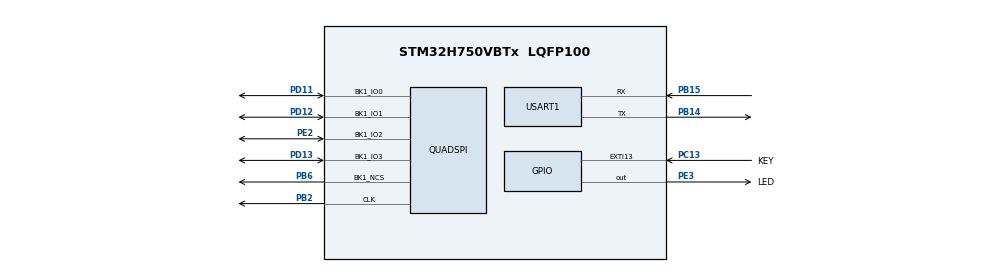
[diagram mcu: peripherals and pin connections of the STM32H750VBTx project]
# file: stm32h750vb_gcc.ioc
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CORTEX_M7.AccessPermission_S-Cortex_Memory_Protection_Unit_Region1_Settings_S=MPU_REGION_PRIV_RO
CORTEX_M7.BaseAddress_S-Cortex_Memory_Protection_Unit_Region1_Settings_S=0x08000000
CORTEX_M7.BaseAddress_Spec=QSPI_BASE
CORTEX_M7.CPU_DCache=Disabled
CORTEX_M7.CPU_ICache=Disabled
CORTEX_M7.DisableExec_Spec=MPU_INSTRUCTION_ACCESS_DISABLE
CORTEX_M7.Enable_S-Cortex_Memory_Protection_Unit_Region1_Settings_S=MPU_REGION_ENABLE
CORTEX_M7.IsCacheable_S-Cortex_Memory_Protection_Unit_Region1_Settings_S=MPU_ACCESS_CACHEABLE
CORTEX_M7.IsShareable_Spec=MPU_ACCESS_NOT_SHAREABLE
CORTEX_M7.Size_S-Cortex_Memory_Protection_Unit_Region1_Settings_S=MPU_REGION_SIZE_128KB
CORTEX_M7.Size_Spec=MPU_REGION_SIZE_256MB
CORTEX_M7.SubRegionDisable_Spec=0x00
CORTEX_M7.TypeExtField_Spec=MPU_TEX_LEVEL1
CORTEX_M7.default_mode_Activation=1
Dma.Request0=USART1_RX
Dma.USART1_RX.0.Direction=DMA_PERIPH_TO_MEMORY
Dma.USART1_RX.0.EventEnable=DISABLE
Dma.USART1_RX.0.FIFOMode=DMA_FIFOMODE_DISABLE
Dma.USART1_RX.0.Instance=DMA1_Stream0
Dma.USART1_RX.0.MemDataAlignment=DMA_MDATAALIGN_BYTE
Dma.USART1_RX.0.MemInc=DMA_MINC_ENABLE
Dma.USART1_RX.0.Mode=DMA_CIRCULAR
Dma.USART1_RX.0.PeriphDataAlignment=DMA_PDATAALIGN_BYTE
Dma.USART1_RX.0.PeriphInc=DMA_PINC_DISABLE
Dma.USART1_RX.0.Polarity=HAL_DMAMUX_REQ_GEN_RISING
Dma.USART1_RX.0.Priority=DMA_PRIORITY_LOW
Dma.USART1_RX.0.RequestNumber=1
Dma.USART1_RX.0.SignalID=NONE
Dma.USART1_RX.0.SyncEnable=DISABLE
Dma.USART1_RX.0.SyncPolarity=HAL_DMAMUX_SYNC_NO_EVENT
Dma.USART1_RX.0.SyncRequestNumber=1
Dma.USART1_RX.0.SyncSignalID=NONE
Mcu.Family=STM32H7
Mcu.Name=STM32H750VBTx
Mcu.Package=LQFP100
NVIC.DMA1_Stream0_IRQn=true\:0\:0\:false\:false\:true\:false\:true\:true
NVIC.EXTI15_10_IRQn=true\:0\:0\:true\:false\:true\:true\:true\:true
NVIC.PriorityGroup=NVIC_PRIORITYGROUP_4
NVIC.USART1_IRQn=true\:1\:0\:true\:false\:true\:false\:true\:true
PB14.GPIO_Speed=GPIO_SPEED_FREQ_MEDIUM
PB14.Mode=Asynchronous
PB14.Signal=USART1_TX
PB15.GPIO_Speed=GPIO_SPEED_FREQ_MEDIUM
PB15.Mode=Asynchronous
PB15.Signal=USART1_RX
PB2.GPIO_Speed=GPIO_SPEED_FREQ_VERY_HIGH
PB2.Mode=Single Bank 1
PB2.Signal=QUADSPI_CLK
PB6.GPIO_Speed=GPIO_SPEED_FREQ_VERY_HIGH
PB6.Mode=Single Bank 1
PB6.Signal=QUADSPI_BK1_NCS
PC13.GPIO_Label=KEY
PC13.Signal=GPXTI13
PC14-OSC32_IN\ (OSC32_IN).Mode=LSE-External-Oscillator
PC14-OSC32_IN\ (OSC32_IN).Signal=RCC_OSC32_IN
PC15-OSC32_OUT\ (OSC32_OUT).Mode=LSE-External-Oscillator
PC15-OSC32_OUT\ (OSC32_OUT).Signal=RCC_OSC32_OUT
PD11.GPIO_Speed=GPIO_SPEED_FREQ_VERY_HIGH
PD11.Mode=Single Bank 1
PD11.Signal=QUADSPI_BK1_IO0
PD12.GPIO_Speed=GPIO_SPEED_FREQ_VERY_HIGH
PD12.Mode=Single Bank 1
PD12.Signal=QUADSPI_BK1_IO1
PD13.GPIO_Speed=GPIO_SPEED_FREQ_VERY_HIGH
PD13.Mode=Single Bank 1
PD13.Signal=QUADSPI_BK1_IO3
PE2.GPIO_Speed=GPIO_SPEED_FREQ_VERY_HIGH
PE2.Mode=Single Bank 1
PE2.Signal=QUADSPI_BK1_IO2
PE3.GPIO_Label=LED
PE3.Signal=GPIO_Output
PH0-OSC_IN\ (PH0).Mode=HSE-External-Oscillator
PH0-OSC_IN\ (PH0).Signal=RCC_OSC_IN
PH1-OSC_OUT\ (PH1).Mode=HSE-External-Oscillator
PH1-OSC_OUT\ (PH1).Signal=RCC_OSC_OUT
ProjectManager.HeapSize=0x200
ProjectManager.StackSize=0x400
ProjectManager.TargetToolchain=Makefile
QUADSPI.ChipSelectHighTime=QSPI_CS_HIGH_TIME_6_CYCLE
QUADSPI.ClockMode=QSPI_CLOCK_MODE_3
QUADSPI.ClockPrescaler=1-1
QUADSPI.FifoThreshold=4
QUADSPI.FlashSize=23-1
QUADSPI.SampleShifting=QSPI_SAMPLE_SHIFTING_HALFCYCLE
RCC.ADCFreq_Value=100000000
RCC.APB1Freq_Value=120000000
RCC.APB2Freq_Value=120000000
RCC.APB3Freq_Value=120000000
RCC.APB4Freq_Value=120000000
RCC.CortexFreq_Value=480000000
RCC.D1PPRE=RCC_APB3_DIV2
RCC.D2PPRE1=RCC_APB1_DIV2
RCC.D2PPRE2=RCC_APB2_DIV2
RCC.D3PPRE=RCC_APB4_DIV2
RCC.DIVM1=5
RCC.DIVM2=25
RCC.DIVN1=192
RCC.DIVN2=200
RCC.DIVN3=128
RCC.DIVQ2=20
RCC.HCLKFreq_Value=240000000
RCC.HPRE=RCC_HCLK_DIV2
RCC.PLLSourceVirtual=RCC_PLLSOURCE_HSE
RCC.QSPICLockSelection=RCC_QSPICLKSOURCE_PLL2
RCC.SYSCLKFreq_VALUE=480000000
RCC.SYSCLKSource=RCC_SYSCLKSOURCE_PLLCLK
RCC.USART16CLockSelection=RCC_USART16CLKSOURCE_PLL2
RCC.USBFreq_Value=480000000
USART1.VirtualMode-Asynchronous=VM_ASYNC
VP_MEMORYMAP_VS_MEMORYMAP.Mode=CurAppReg
board=custom

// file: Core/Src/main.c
/* USER CODE BEGIN Header */
/**
 ******************************************************************************
 * @file           : main.c
 * @brief          : Main program body
 ******************************************************************************
 * @attention
 *
 * Copyright (c) 2024 STMicroelectronics.
 * All rights reserved.
 *
 * This software is licensed under terms that can be found in the LICENSE file
 * in the root directory of this software component.
 * If no LICENSE file comes with this software, it is provided AS-IS.
 *
 ******************************************************************************
 */
/* USER CODE END Header */
#include "main.h"
#include "dma.h"
#include "memorymap.h"
#include "quadspi.h"
#include "usart.h"
#include "gpio.h"

/* USER CODE BEGIN Includes */
#include "RingBuffer.h"
#include "w25qxx_qspi.h"
/* USER CODE END Includes */

/* USER CODE BEGIN PV */
uint8_t USART1_Rx_buf[1024] = {0};
uint8_t USART1_Tx_buf[1024] = {0};
RingBuffer usart1_fifo		= {0};
extern uint16_t w25qxx_ID;
/* USER CODE END PV */

void SystemClock_Config(void);
void PeriphCommonClock_Config(void);
static void MPU_Config(void);

int main(void)
{

	/* MPU Configuration--------------------------------------------------------*/
	MPU_Config();

	/* MCU Configuration--------------------------------------------------------*/

	/* Reset of all peripherals, Initializes the Flash interface and the Systick. */
	HAL_Init();

	/* USER CODE BEGIN Init */
	// SCB->CACR |= 1 << 2;
	/* USER CODE END Init */

	/* Configure the system clock */
	SystemClock_Config();

	/* Configure the peripherals common clocks */
	PeriphCommonClock_Config();

	/* Initialize all configured peripherals */
	MX_GPIO_Init();
	MX_DMA_Init();
	MX_USART1_UART_Init();
	MX_QUADSPI_Init();
	/* USER CODE BEGIN 2 */
	w25qxx_Init();
	printf("deviceID: 0x%x\n", w25qxx_ID);
	HAL_UARTEx_ReceiveToIdle_DMA(&huart1, USART1_Rx_buf, sizeof(USART1_Rx_buf));
	/* USER CODE END 2 */

	/* Infinite loop */
	/* USER CODE BEGIN WHILE */
	while (1) {
		if (usart1_fifo.head != usart1_fifo.tail) {
			HAL_UART_Transmit(&huart1, USART1_Tx_buf, RB_GetByte_Bulk(&usart1_fifo, USART1_Tx_buf, RB_GetAvailable(&usart1_fifo)), 500);
		}
		/* USER CODE END WHILE */

	}
}

void SystemClock_Config(void)
{
	RCC_OscInitTypeDef RCC_OscInitStruct = {0};
	RCC_ClkInitTypeDef RCC_ClkInitStruct = {0};

	/** Supply configuration update enable
	 */
	HAL_PWREx_ConfigSupply(PWR_LDO_SUPPLY);

	/** Configure the main internal regulator output voltage
	 */
	__HAL_PWR_VOLTAGESCALING_CONFIG(PWR_REGULATOR_VOLTAGE_SCALE0);

	while (!__HAL_PWR_GET_FLAG(PWR_FLAG_VOSRDY)) {}

	/** Initializes the RCC Oscillators according to the specified parameters
	 * in the RCC_OscInitTypeDef structure.
	 */
	RCC_OscInitStruct.OscillatorType = RCC_OSCILLATORTYPE_HSE;
	RCC_OscInitStruct.HSEState		 = RCC_HSE_ON;
	RCC_OscInitStruct.PLL.PLLState	 = RCC_PLL_ON;
	RCC_OscInitStruct.PLL.PLLSource	 = RCC_PLLSOURCE_HSE;
	RCC_OscInitStruct.PLL.PLLM		 = 5;
	RCC_OscInitStruct.PLL.PLLN		 = 192;
	RCC_OscInitStruct.PLL.PLLP		 = 2;
	RCC_OscInitStruct.PLL.PLLQ		 = 2;
	RCC_OscInitStruct.PLL.PLLR		 = 2;
	RCC_OscInitStruct.PLL.PLLRGE	 = RCC_PLL1VCIRANGE_2;
	RCC_OscInitStruct.PLL.PLLVCOSEL	 = RCC_PLL1VCOWIDE;
	RCC_OscInitStruct.PLL.PLLFRACN	 = 0;
	if (HAL_RCC_OscConfig(&RCC_OscInitStruct) != HAL_OK) {
		Error_Handler();
	}

	/** Initializes the CPU, AHB and APB buses clocks
	 */
	RCC_ClkInitStruct.ClockType		 = RCC_CLOCKTYPE_HCLK | RCC_CLOCKTYPE_SYSCLK | RCC_CLOCKTYPE_PCLK1 | RCC_CLOCKTYPE_PCLK2 | RCC_CLOCKTYPE_D3PCLK1 | RCC_CLOCKTYPE_D1PCLK1;
	RCC_ClkInitStruct.SYSCLKSource	 = RCC_SYSCLKSOURCE_PLLCLK;
	RCC_ClkInitStruct.SYSCLKDivider	 = RCC_SYSCLK_DIV1;
	RCC_ClkInitStruct.AHBCLKDivider	 = RCC_HCLK_DIV2;
	RCC_ClkInitStruct.APB3CLKDivider = RCC_APB3_DIV2;
	RCC_ClkInitStruct.APB1CLKDivider = RCC_APB1_DIV2;
	RCC_ClkInitStruct.APB2CLKDivider = RCC_APB2_DIV2;
	RCC_ClkInitStruct.APB4CLKDivider = RCC_APB4_DIV2;

	if (HAL_RCC_ClockConfig(&RCC_ClkInitStruct, FLASH_LATENCY_4) != HAL_OK) {
		Error_Handler();
	}
}

void PeriphCommonClock_Config(void)
{
	RCC_PeriphCLKInitTypeDef PeriphClkInitStruct = {0};

	/** Initializes the peripherals clock
	 */
	PeriphClkInitStruct.PeriphClockSelection  = RCC_PERIPHCLK_QSPI | RCC_PERIPHCLK_USART1;
	PeriphClkInitStruct.PLL2.PLL2M			  = 25;
	PeriphClkInitStruct.PLL2.PLL2N			  = 200;
	PeriphClkInitStruct.PLL2.PLL2P			  = 2;
	PeriphClkInitStruct.PLL2.PLL2Q			  = 20;
	PeriphClkInitStruct.PLL2.PLL2R			  = 2;
	PeriphClkInitStruct.PLL2.PLL2RGE		  = RCC_PLL2VCIRANGE_0;
	PeriphClkInitStruct.PLL2.PLL2VCOSEL		  = RCC_PLL2VCOWIDE;
	PeriphClkInitStruct.PLL2.PLL2FRACN		  = 0;
	PeriphClkInitStruct.QspiClockSelection	  = RCC_QSPICLKSOURCE_PLL2;
	PeriphClkInitStruct.Usart16ClockSelection = RCC_USART16CLKSOURCE_PLL2;
	if (HAL_RCCEx_PeriphCLKConfig(&PeriphClkInitStruct) != HAL_OK) {
		Error_Handler();
	}
}

/* MPU Configuration */

void MPU_Config(void)
{
	MPU_Region_InitTypeDef MPU_InitStruct = {0};

	/* Disables the MPU */
	HAL_MPU_Disable();

	/** Initializes and configures the Region and the memory to be protected
	 */
	MPU_InitStruct.Enable			= MPU_REGION_ENABLE;
	MPU_InitStruct.Number			= MPU_REGION_NUMBER0;
	MPU_InitStruct.BaseAddress		= QSPI_BASE;
	MPU_InitStruct.Size				= MPU_REGION_SIZE_256MB;
	MPU_InitStruct.SubRegionDisable = 0x00;
	MPU_InitStruct.TypeExtField		= MPU_TEX_LEVEL1;
	MPU_InitStruct.AccessPermission = MPU_REGION_NO_ACCESS;
	MPU_InitStruct.DisableExec		= MPU_INSTRUCTION_ACCESS_DISABLE;
	MPU_InitStruct.IsShareable		= MPU_ACCESS_NOT_SHAREABLE;
	MPU_InitStruct.IsCacheable		= MPU_ACCESS_NOT_CACHEABLE;
	MPU_InitStruct.IsBufferable		= MPU_ACCESS_NOT_BUFFERABLE;

	HAL_MPU_ConfigRegion(&MPU_InitStruct);

	/** Initializes and configures the Region and the memory to be protected
	 */
	MPU_InitStruct.Number			= MPU_REGION_NUMBER1;
	MPU_InitStruct.BaseAddress		= 0x08000000;
	MPU_InitStruct.Size				= MPU_REGION_SIZE_128KB;
	MPU_InitStruct.SubRegionDisable = 0x0;
	MPU_InitStruct.TypeExtField		= MPU_TEX_LEVEL0;
	MPU_InitStruct.AccessPermission = MPU_REGION_PRIV_RO;
	MPU_InitStruct.DisableExec		= MPU_INSTRUCTION_ACCESS_ENABLE;
	MPU_InitStruct.IsCacheable		= MPU_ACCESS_CACHEABLE;

	HAL_MPU_ConfigRegion(&MPU_InitStruct);
	/* Enables the MPU */
	HAL_MPU_Enable(MPU_PRIVILEGED_DEFAULT);
}

void Error_Handler(void)
{
	__disable_irq();
	while (1) {
	}
}
